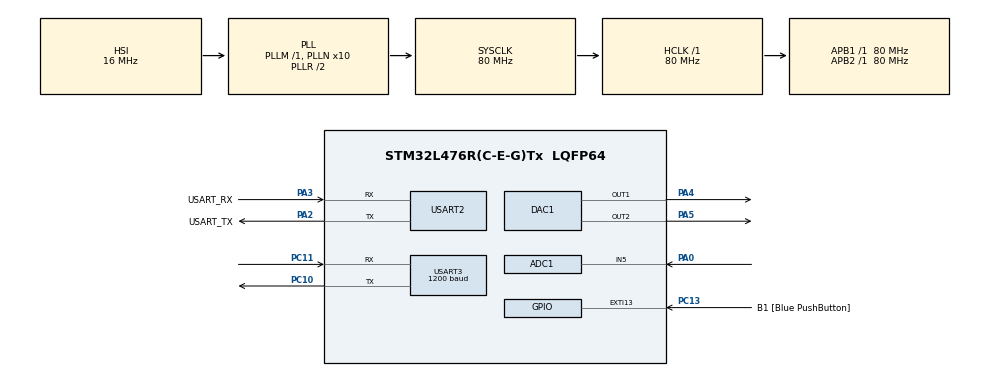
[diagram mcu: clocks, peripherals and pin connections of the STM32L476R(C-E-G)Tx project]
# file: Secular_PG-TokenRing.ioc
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ADC1.Channel-0\#ChannelRegularConversion=ADC_CHANNEL_5
ADC1.ContinuousConvMode=DISABLE
ADC1.DMAContinuousRequests=ENABLE
ADC1.ExternalTrigConv=ADC_EXTERNALTRIG_T4_TRGO
ADC1.NbrOfConversionFlag=1
ADC1.OffsetNumber-0\#ChannelRegularConversion=ADC_OFFSET_NONE
ADC1.Rank-0\#ChannelRegularConversion=1
ADC1.SamplingTime-0\#ChannelRegularConversion=ADC_SAMPLETIME_2CYCLES_5
ADC1.master=1
DAC1.DAC_Channel-DAC_OUT2=DAC_CHANNEL_2
DAC1.DAC_SampleAndHold-DAC_OUT1=DAC_SAMPLEANDHOLD_DISABLE
DAC1.DAC_Trigger-DAC_OUT1=DAC_TRIGGER_T2_TRGO
DAC1.DAC_Trigger-DAC_OUT2=DAC_TRIGGER_T5_TRGO
DAC1.WaveGeneration-DAC_OUT1=NoiseWaveGeneration
DAC1.WaveGeneration-DAC_OUT2=NoiseWaveGeneration
Dma.ADC1.2.Direction=DMA_PERIPH_TO_MEMORY
Dma.ADC1.2.Instance=DMA1_Channel1
Dma.ADC1.2.MemDataAlignment=DMA_MDATAALIGN_HALFWORD
Dma.ADC1.2.MemInc=DMA_MINC_ENABLE
Dma.ADC1.2.Mode=DMA_NORMAL
Dma.ADC1.2.PeriphDataAlignment=DMA_PDATAALIGN_HALFWORD
Dma.ADC1.2.PeriphInc=DMA_PINC_DISABLE
Dma.ADC1.2.Priority=DMA_PRIORITY_HIGH
Dma.DAC_CH1.0.Direction=DMA_MEMORY_TO_PERIPH
Dma.DAC_CH1.0.Instance=DMA1_Channel3
Dma.DAC_CH1.0.MemDataAlignment=DMA_MDATAALIGN_HALFWORD
Dma.DAC_CH1.0.MemInc=DMA_MINC_ENABLE
Dma.DAC_CH1.0.Mode=DMA_CIRCULAR
Dma.DAC_CH1.0.PeriphDataAlignment=DMA_PDATAALIGN_HALFWORD
Dma.DAC_CH1.0.PeriphInc=DMA_PINC_DISABLE
Dma.DAC_CH1.0.Priority=DMA_PRIORITY_HIGH
Dma.DAC_CH2.1.Direction=DMA_MEMORY_TO_PERIPH
Dma.DAC_CH2.1.Instance=DMA1_Channel4
Dma.DAC_CH2.1.MemDataAlignment=DMA_MDATAALIGN_HALFWORD
Dma.DAC_CH2.1.MemInc=DMA_MINC_ENABLE
Dma.DAC_CH2.1.Mode=DMA_CIRCULAR
Dma.DAC_CH2.1.PeriphDataAlignment=DMA_PDATAALIGN_HALFWORD
Dma.DAC_CH2.1.PeriphInc=DMA_PINC_DISABLE
Dma.DAC_CH2.1.Priority=DMA_PRIORITY_HIGH
Dma.Request0=DAC_CH1
Dma.Request1=DAC_CH2
Dma.Request2=ADC1
FREERTOS.Tasks01=defaultTask,0,1024,StartDefaultTask,Default,NULL,Dynamic,NULL,NULL
FREERTOS.configMINIMAL_STACK_SIZE=1024
FREERTOS.configTOTAL_HEAP_SIZE=30000
FREERTOS.configUSE_NEWLIB_REENTRANT=1
Mcu.Family=STM32L4
Mcu.Name=STM32L476R(C-E-G)Tx
Mcu.Package=LQFP64
NVIC.DMA1_Channel1_IRQn=true\:5\:0\:false\:false\:true\:true\:false\:true\:true
NVIC.DMA1_Channel3_IRQn=true\:5\:0\:false\:false\:true\:true\:false\:true\:true
NVIC.DMA1_Channel4_IRQn=true\:5\:0\:false\:false\:true\:true\:false\:true\:true
NVIC.PriorityGroup=NVIC_PRIORITYGROUP_4
NVIC.TIM3_IRQn=true\:15\:0\:false\:false\:true\:false\:false\:true\:true
NVIC.TimeBase=TIM3_IRQn
NVIC.TimeBaseIP=TIM3
NVIC.USART3_IRQn=true\:5\:0\:false\:false\:true\:true\:true\:true\:true
PA0.Signal=ADCx_IN5
PA13\ (JTMS-SWDIO).GPIO_Label=TMS
PA13\ (JTMS-SWDIO).Mode=Serial_Wire
PA13\ (JTMS-SWDIO).Signal=SYS_JTMS-SWDIO
PA14\ (JTCK-SWCLK).GPIO_Label=TCK
PA14\ (JTCK-SWCLK).Mode=Serial_Wire
PA14\ (JTCK-SWCLK).Signal=SYS_JTCK-SWCLK
PA2.GPIO_Label=USART_TX
PA2.GPIO_Mode=GPIO_MODE_AF_PP
PA2.GPIO_PuPd=GPIO_NOPULL
PA2.GPIO_Speed=GPIO_SPEED_FREQ_VERY_HIGH
PA2.Mode=Asynchronous
PA2.Signal=USART2_TX
PA3.GPIO_Label=USART_RX
PA3.GPIO_Mode=GPIO_MODE_AF_PP
PA3.GPIO_PuPd=GPIO_NOPULL
PA3.GPIO_Speed=GPIO_SPEED_FREQ_VERY_HIGH
PA3.Mode=Asynchronous
PA3.Signal=USART2_RX
PA4.Signal=COMP_DAC11_group
PA5.Signal=COMP_DAC12_group
PB3\ (JTDO-TRACESWO).GPIO_Label=SWO
PB3\ (JTDO-TRACESWO).Signal=SYS_JTDO-SWO
PC10.Mode=Asynchronous
PC10.Signal=USART3_TX
PC11.Mode=Asynchronous
PC11.Signal=USART3_RX
PC13.GPIO_Label=B1 [Blue PushButton]
PC13.GPIO_ModeDefaultEXTI=GPIO_MODE_IT_FALLING
PC13.GPIO_PuPd=GPIO_NOPULL
PC13.Signal=GPXTI13
PC14-OSC32_IN\ (PC14).Mode=LSE-External-Oscillator
PC14-OSC32_IN\ (PC14).Signal=RCC_OSC32_IN
PC15-OSC32_OUT\ (PC15).Mode=LSE-External-Oscillator
PC15-OSC32_OUT\ (PC15).Signal=RCC_OSC32_OUT
PH0-OSC_IN\ (PH0).Signal=RCC_OSC_IN
PH1-OSC_OUT\ (PH1).Signal=RCC_OSC_OUT
ProjectManager.HeapSize=0x200
ProjectManager.StackSize=0x400
ProjectManager.TargetToolchain=STM32CubeIDE
RCC.ADCFreq_Value=64000000
RCC.AHBFreq_Value=80000000
RCC.APB1Freq_Value=80000000
RCC.APB1TimFreq_Value=80000000
RCC.APB2Freq_Value=80000000
RCC.APB2TimFreq_Value=80000000
RCC.CortexFreq_Value=80000000
RCC.HCLKFreq_Value=80000000
RCC.HSE_VALUE=8000000
RCC.HSI_VALUE=16000000
RCC.MSI_VALUE=4000000
RCC.PLLN=10
RCC.PLLSAI1Q=RCC_PLLQ_DIV4
RCC.PLLSourceVirtual=RCC_PLLSOURCE_HSI
RCC.PREFETCH_ENABLE=1
RCC.SYSCLKFreq_VALUE=80000000
RCC.SYSCLKSource=RCC_SYSCLKSOURCE_PLLCLK
RCC.USART3CLockSelection=RCC_USART3CLKSOURCE_HSI
RCC.USBFreq_Value=32000000
RCC.VCOOutputFreq_Value=160000000
SH.ADCx_IN5.0=ADC1_IN5,IN5-Single-Ended
SH.COMP_DAC11_group.0=DAC1_OUT1,DAC_OUT1
SH.COMP_DAC12_group.0=DAC1_OUT2,DAC_OUT2
TIM2.AutoReloadPreload=TIM_AUTORELOAD_PRELOAD_DISABLE
TIM2.Channel-Output\ Compare1\ No\ Output=TIM_CHANNEL_1
TIM2.CounterMode=TIM_COUNTERMODE_UP
TIM2.OCMode_1=TIM_OCMODE_RETRIGERRABLE_OPM1
TIM2.Period=1000
TIM2.Prescaler=79
TIM2.TIM_MasterOutputTrigger=TIM_TRGO_UPDATE
TIM4.Period=7999
TIM4.Prescaler=0
TIM4.TIM_MasterOutputTrigger=TIM_TRGO_UPDATE
TIM5.Prescaler=79
TIM5.TIM_MasterOutputTrigger=TIM_TRGO_UPDATE
USART2.VirtualMode-Asynchronous=VM_ASYNC
USART3.BaudRate=1200
USART3.VirtualMode-Asynchronous=VM_ASYNC
VP_FREERTOS_VS_CMSIS_V1.Mode=CMSIS_V1
VP_RNG_VS_RNG.Mode=RNG_Activate
VP_SYS_VS_tim3.Mode=TIM3
VP_TIM1_VS_ClockSourceINT.Mode=Internal
VP_TIM2_VS_ClockSourceINT.Mode=Internal
VP_TIM2_VS_no_output1.Mode=Output Compare1 No Output
VP_TIM4_VS_ClockSourceINT.Mode=Internal
VP_TIM5_VS_ClockSourceINT.Mode=Internal
board=NUCLEO-L476RG

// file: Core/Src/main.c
/* USER CODE BEGIN Header */
/**
  ******************************************************************************
  * @file           : main.c
  * @brief          : Main program body
  ******************************************************************************
  * @attention
  *
  * Copyright (c) 2023 STMicroelectronics.
  * All rights reserved.
  *
  * This software is licensed under terms that can be found in the LICENSE file
  * in the root directory of this software component.
  * If no LICENSE file comes with this software, it is provided AS-IS.
  *
  ******************************************************************************
  */
/* USER CODE END Header */
#include "main.h"
#include "cmsis_os.h"

ADC_HandleTypeDef hadc1;
DMA_HandleTypeDef hdma_adc1;

DAC_HandleTypeDef hdac1;
DMA_HandleTypeDef hdma_dac_ch1;
DMA_HandleTypeDef hdma_dac_ch2;

RNG_HandleTypeDef hrng;

TIM_HandleTypeDef htim1;
TIM_HandleTypeDef htim2;
TIM_HandleTypeDef htim4;
TIM_HandleTypeDef htim5;

UART_HandleTypeDef huart2;
UART_HandleTypeDef huart3;

osThreadId defaultTaskHandle;

void SystemClock_Config(void);
void PeriphCommonClock_Config(void);
static void MX_GPIO_Init(void);
static void MX_DMA_Init(void);
static void MX_USART2_UART_Init(void);
static void MX_DAC1_Init(void);
static void MX_RNG_Init(void);
static void MX_TIM2_Init(void);
static void MX_TIM1_Init(void);
static void MX_TIM5_Init(void);
static void MX_ADC1_Init(void);
static void MX_TIM4_Init(void);
static void MX_USART3_UART_Init(void);
void StartDefaultTask(void const * argument);

int main(void)
{

  /* MCU Configuration--------------------------------------------------------*/

  /* Reset of all peripherals, Initializes the Flash interface and the Systick. */
  HAL_Init();

  /* Configure the system clock */
  SystemClock_Config();

/* Configure the peripherals common clocks */
  PeriphCommonClock_Config();

  /* Initialize all configured peripherals */
  MX_GPIO_Init();
  MX_DMA_Init();
  MX_USART2_UART_Init();
  MX_DAC1_Init();
  MX_RNG_Init();
  MX_TIM2_Init();
  MX_TIM1_Init();
  MX_TIM5_Init();
  MX_ADC1_Init();
  MX_TIM4_Init();
  MX_USART3_UART_Init();

  /* Create the thread(s) */
  /* definition and creation of defaultTask */
  osThreadDef(defaultTask, StartDefaultTask, osPriorityNormal, 0, 1024);
  defaultTaskHandle = osThreadCreate(osThread(defaultTask), NULL);

  /* USER CODE BEGIN RTOS_THREADS */
  /* add threads, ... */
  app_init();
  /* USER CODE END RTOS_THREADS */

  /* Start scheduler */
  osKernelStart();
  /* We should never get here as control is now taken by the scheduler */
  /* Infinite loop */
  while (1)
  {

  }
}

void SystemClock_Config(void)
{
  RCC_OscInitTypeDef RCC_OscInitStruct = {0};
  RCC_ClkInitTypeDef RCC_ClkInitStruct = {0};

  /** Configure the main internal regulator output voltage
  */
  if (HAL_PWREx_ControlVoltageScaling(PWR_REGULATOR_VOLTAGE_SCALE1) != HAL_OK)
  {
    Error_Handler();
  }

  /** Initializes the RCC Oscillators according to the specified parameters
  * in the RCC_OscInitTypeDef structure.
  */
  RCC_OscInitStruct.OscillatorType = RCC_OSCILLATORTYPE_HSI;
  RCC_OscInitStruct.HSIState = RCC_HSI_ON;
  RCC_OscInitStruct.HSICalibrationValue = RCC_HSICALIBRATION_DEFAULT;
  RCC_OscInitStruct.PLL.PLLState = RCC_PLL_ON;
  RCC_OscInitStruct.PLL.PLLSource = RCC_PLLSOURCE_HSI;
  RCC_OscInitStruct.PLL.PLLM = 1;
  RCC_OscInitStruct.PLL.PLLN = 10;
  RCC_OscInitStruct.PLL.PLLP = RCC_PLLP_DIV7;
  RCC_OscInitStruct.PLL.PLLQ = RCC_PLLQ_DIV2;
  RCC_OscInitStruct.PLL.PLLR = RCC_PLLR_DIV2;
  if (HAL_RCC_OscConfig(&RCC_OscInitStruct) != HAL_OK)
  {
    Error_Handler();
  }

  /** Initializes the CPU, AHB and APB buses clocks
  */
  RCC_ClkInitStruct.ClockType = RCC_CLOCKTYPE_HCLK|RCC_CLOCKTYPE_SYSCLK
                              |RCC_CLOCKTYPE_PCLK1|RCC_CLOCKTYPE_PCLK2;
  RCC_ClkInitStruct.SYSCLKSource = RCC_SYSCLKSOURCE_PLLCLK;
  RCC_ClkInitStruct.AHBCLKDivider = RCC_SYSCLK_DIV1;
  RCC_ClkInitStruct.APB1CLKDivider = RCC_HCLK_DIV1;
  RCC_ClkInitStruct.APB2CLKDivider = RCC_HCLK_DIV1;

  if (HAL_RCC_ClockConfig(&RCC_ClkInitStruct, FLASH_LATENCY_4) != HAL_OK)
  {
    Error_Handler();
  }
}

void PeriphCommonClock_Config(void)
{
  RCC_PeriphCLKInitTypeDef PeriphClkInit = {0};

  /** Initializes the peripherals clock
  */
  PeriphClkInit.PeriphClockSelection = RCC_PERIPHCLK_RNG|RCC_PERIPHCLK_ADC;
  PeriphClkInit.AdcClockSelection = RCC_ADCCLKSOURCE_PLLSAI1;
  PeriphClkInit.RngClockSelection = RCC_RNGCLKSOURCE_PLLSAI1;
  PeriphClkInit.PLLSAI1.PLLSAI1Source = RCC_PLLSOURCE_HSI;
  PeriphClkInit.PLLSAI1.PLLSAI1M = 1;
  PeriphClkInit.PLLSAI1.PLLSAI1N = 8;
  PeriphClkInit.PLLSAI1.PLLSAI1P = RCC_PLLP_DIV7;
  PeriphClkInit.PLLSAI1.PLLSAI1Q = RCC_PLLQ_DIV4;
  PeriphClkInit.PLLSAI1.PLLSAI1R = RCC_PLLR_DIV2;
  PeriphClkInit.PLLSAI1.PLLSAI1ClockOut = RCC_PLLSAI1_48M2CLK|RCC_PLLSAI1_ADC1CLK;
  if (HAL_RCCEx_PeriphCLKConfig(&PeriphClkInit) != HAL_OK)
  {
    Error_Handler();
  }
}

static void MX_ADC1_Init(void)
{

  ADC_MultiModeTypeDef multimode = {0};
  ADC_ChannelConfTypeDef sConfig = {0};

  /** Common config
  */
  hadc1.Instance = ADC1;
  hadc1.Init.ClockPrescaler = ADC_CLOCK_ASYNC_DIV1;
  hadc1.Init.Resolution = ADC_RESOLUTION_12B;
  hadc1.Init.DataAlign = ADC_DATAALIGN_RIGHT;
  hadc1.Init.ScanConvMode = ADC_SCAN_DISABLE;
  hadc1.Init.EOCSelection = ADC_EOC_SINGLE_CONV;
  hadc1.Init.LowPowerAutoWait = DISABLE;
  hadc1.Init.ContinuousConvMode = DISABLE;
  hadc1.Init.NbrOfConversion = 1;
  hadc1.Init.DiscontinuousConvMode = DISABLE;
  hadc1.Init.ExternalTrigConv = ADC_EXTERNALTRIG_T4_TRGO;
  hadc1.Init.ExternalTrigConvEdge = ADC_EXTERNALTRIGCONVEDGE_RISING;
  hadc1.Init.DMAContinuousRequests = ENABLE;
  hadc1.Init.Overrun = ADC_OVR_DATA_PRESERVED;
  hadc1.Init.OversamplingMode = DISABLE;
  if (HAL_ADC_Init(&hadc1) != HAL_OK)
  {
    Error_Handler();
  }

  /** Configure the ADC multi-mode
  */
  multimode.Mode = ADC_MODE_INDEPENDENT;
  if (HAL_ADCEx_MultiModeConfigChannel(&hadc1, &multimode) != HAL_OK)
  {
    Error_Handler();
  }

  /** Configure Regular Channel
  */
  sConfig.Channel = ADC_CHANNEL_5;
  sConfig.Rank = ADC_REGULAR_RANK_1;
  sConfig.SamplingTime = ADC_SAMPLETIME_2CYCLES_5;
  sConfig.SingleDiff = ADC_SINGLE_ENDED;
  sConfig.OffsetNumber = ADC_OFFSET_NONE;
  sConfig.Offset = 0;
  if (HAL_ADC_ConfigChannel(&hadc1, &sConfig) != HAL_OK)
  {
    Error_Handler();
  }

}

static void MX_DAC1_Init(void)
{

  DAC_ChannelConfTypeDef sConfig = {0};

  /** DAC Initialization
  */
  hdac1.Instance = DAC1;
  if (HAL_DAC_Init(&hdac1) != HAL_OK)
  {
    Error_Handler();
  }

  /** DAC channel OUT1 config
  */
  sConfig.DAC_SampleAndHold = DAC_SAMPLEANDHOLD_DISABLE;
  sConfig.DAC_Trigger = DAC_TRIGGER_T2_TRGO;
  sConfig.DAC_OutputBuffer = DAC_OUTPUTBUFFER_ENABLE;
  sConfig.DAC_ConnectOnChipPeripheral = DAC_CHIPCONNECT_DISABLE;
  sConfig.DAC_UserTrimming = DAC_TRIMMING_FACTORY;
  if (HAL_DAC_ConfigChannel(&hdac1, &sConfig, DAC_CHANNEL_1) != HAL_OK)
  {
    Error_Handler();
  }

  /** Configure Noise wave generation on DAC OUT1
  */
  if (HAL_DACEx_NoiseWaveGenerate(&hdac1, DAC_CHANNEL_1, DAC_LFSRUNMASK_BIT0) != HAL_OK)
  {
    Error_Handler();
  }

  /** DAC channel OUT2 config
  */
  sConfig.DAC_Trigger = DAC_TRIGGER_T5_TRGO;
  if (HAL_DAC_ConfigChannel(&hdac1, &sConfig, DAC_CHANNEL_2) != HAL_OK)
  {
    Error_Handler();
  }

  /** Configure Noise wave generation on DAC OUT2
  */
  if (HAL_DACEx_NoiseWaveGenerate(&hdac1, DAC_CHANNEL_2, DAC_LFSRUNMASK_BIT0) != HAL_OK)
  {
    Error_Handler();
  }

}

static void MX_RNG_Init(void)
{

  hrng.Instance = RNG;
  if (HAL_RNG_Init(&hrng) != HAL_OK)
  {
    Error_Handler();
  }

}

static void MX_TIM1_Init(void)
{

  TIM_ClockConfigTypeDef sClockSourceConfig = {0};
  TIM_MasterConfigTypeDef sMasterConfig = {0};

  htim1.Instance = TIM1;
  htim1.Init.Prescaler = 0;
  htim1.Init.CounterMode = TIM_COUNTERMODE_UP;
  htim1.Init.Period = 65535;
  htim1.Init.ClockDivision = TIM_CLOCKDIVISION_DIV1;
  htim1.Init.RepetitionCounter = 0;
  htim1.Init.AutoReloadPreload = TIM_AUTORELOAD_PRELOAD_DISABLE;
  if (HAL_TIM_Base_Init(&htim1) != HAL_OK)
  {
    Error_Handler();
  }
  sClockSourceConfig.ClockSource = TIM_CLOCKSOURCE_INTERNAL;
  if (HAL_TIM_ConfigClockSource(&htim1, &sClockSourceConfig) != HAL_OK)
  {
    Error_Handler();
  }
  sMasterConfig.MasterOutputTrigger = TIM_TRGO_RESET;
  sMasterConfig.MasterOutputTrigger2 = TIM_TRGO2_RESET;
  sMasterConfig.MasterSlaveMode = TIM_MASTERSLAVEMODE_DISABLE;
  if (HAL_TIMEx_MasterConfigSynchronization(&htim1, &sMasterConfig) != HAL_OK)
  {
    Error_Handler();
  }

}

static void MX_TIM2_Init(void)
{

  TIM_ClockConfigTypeDef sClockSourceConfig = {0};
  TIM_MasterConfigTypeDef sMasterConfig = {0};
  TIM_OC_InitTypeDef sConfigOC = {0};

  htim2.Instance = TIM2;
  htim2.Init.Prescaler = 79;
  htim2.Init.CounterMode = TIM_COUNTERMODE_UP;
  htim2.Init.Period = 1000;
  htim2.Init.ClockDivision = TIM_CLOCKDIVISION_DIV1;
  htim2.Init.AutoReloadPreload = TIM_AUTORELOAD_PRELOAD_DISABLE;
  if (HAL_TIM_Base_Init(&htim2) != HAL_OK)
  {
    Error_Handler();
  }
  sClockSourceConfig.ClockSource = TIM_CLOCKSOURCE_INTERNAL;
  if (HAL_TIM_ConfigClockSource(&htim2, &sClockSourceConfig) != HAL_OK)
  {
    Error_Handler();
  }
  if (HAL_TIM_OC_Init(&htim2) != HAL_OK)
  {
    Error_Handler();
  }
  sMasterConfig.MasterOutputTrigger = TIM_TRGO_UPDATE;
  sMasterConfig.MasterSlaveMode = TIM_MASTERSLAVEMODE_DISABLE;
  if (HAL_TIMEx_MasterConfigSynchronization(&htim2, &sMasterConfig) != HAL_OK)
  {
    Error_Handler();
  }
  sConfigOC.OCMode = TIM_OCMODE_RETRIGERRABLE_OPM1;
  sConfigOC.Pulse = 0;
  sConfigOC.OCPolarity = TIM_OCPOLARITY_HIGH;
  sConfigOC.OCFastMode = TIM_OCFAST_DISABLE;
  if (HAL_TIM_OC_ConfigChannel(&htim2, &sConfigOC, TIM_CHANNEL_1) != HAL_OK)
  {
    Error_Handler();
  }

}

static void MX_TIM4_Init(void)
{

  TIM_ClockConfigTypeDef sClockSourceConfig = {0};
  TIM_MasterConfigTypeDef sMasterConfig = {0};

  htim4.Instance = TIM4;
  htim4.Init.Prescaler = 0;
  htim4.Init.CounterMode = TIM_COUNTERMODE_UP;
  htim4.Init.Period = 7999;
  htim4.Init.ClockDivision = TIM_CLOCKDIVISION_DIV1;
  htim4.Init.AutoReloadPreload = TIM_AUTORELOAD_PRELOAD_DISABLE;
  if (HAL_TIM_Base_Init(&htim4) != HAL_OK)
  {
    Error_Handler();
  }
  sClockSourceConfig.ClockSource = TIM_CLOCKSOURCE_INTERNAL;
  if (HAL_TIM_ConfigClockSource(&htim4, &sClockSourceConfig) != HAL_OK)
  {
    Error_Handler();
  }
  sMasterConfig.MasterOutputTrigger = TIM_TRGO_UPDATE;
  sMasterConfig.MasterSlaveMode = TIM_MASTERSLAVEMODE_DISABLE;
  if (HAL_TIMEx_MasterConfigSynchronization(&htim4, &sMasterConfig) != HAL_OK)
  {
    Error_Handler();
  }

}

static void MX_TIM5_Init(void)
{

  TIM_ClockConfigTypeDef sClockSourceConfig = {0};
  TIM_MasterConfigTypeDef sMasterConfig = {0};

  htim5.Instance = TIM5;
  htim5.Init.Prescaler = 79;
  htim5.Init.CounterMode = TIM_COUNTERMODE_UP;
  htim5.Init.Period = 4294967295;
  htim5.Init.ClockDivision = TIM_CLOCKDIVISION_DIV1;
  htim5.Init.AutoReloadPreload = TIM_AUTORELOAD_PRELOAD_DISABLE;
  if (HAL_TIM_Base_Init(&htim5) != HAL_OK)
  {
    Error_Handler();
  }
  sClockSourceConfig.ClockSource = TIM_CLOCKSOURCE_INTERNAL;
  if (HAL_TIM_ConfigClockSource(&htim5, &sClockSourceConfig) != HAL_OK)
  {
    Error_Handler();
  }
  sMasterConfig.MasterOutputTrigger = TIM_TRGO_UPDATE;
  sMasterConfig.MasterSlaveMode = TIM_MASTERSLAVEMODE_DISABLE;
  if (HAL_TIMEx_MasterConfigSynchronization(&htim5, &sMasterConfig) != HAL_OK)
  {
    Error_Handler();
  }

}

static void MX_USART2_UART_Init(void)
{

  huart2.Instance = USART2;
  huart2.Init.BaudRate = 115200;
  huart2.Init.WordLength = UART_WORDLENGTH_8B;
  huart2.Init.StopBits = UART_STOPBITS_1;
  huart2.Init.Parity = UART_PARITY_NONE;
  huart2.Init.Mode = UART_MODE_TX_RX;
  huart2.Init.HwFlowCtl = UART_HWCONTROL_NONE;
  huart2.Init.OverSampling = UART_OVERSAMPLING_16;
  huart2.Init.OneBitSampling = UART_ONE_BIT_SAMPLE_DISABLE;
  huart2.AdvancedInit.AdvFeatureInit = UART_ADVFEATURE_NO_INIT;
  if (HAL_UART_Init(&huart2) != HAL_OK)
  {
    Error_Handler();
  }

}

static void MX_USART3_UART_Init(void)
{

  huart3.Instance = USART3;
  huart3.Init.BaudRate = 1200;
  huart3.Init.WordLength = UART_WORDLENGTH_8B;
  huart3.Init.StopBits = UART_STOPBITS_1;
  huart3.Init.Parity = UART_PARITY_NONE;
  huart3.Init.Mode = UART_MODE_TX_RX;
  huart3.Init.HwFlowCtl = UART_HWCONTROL_NONE;
  huart3.Init.OverSampling = UART_OVERSAMPLING_16;
  huart3.Init.OneBitSampling = UART_ONE_BIT_SAMPLE_DISABLE;
  huart3.AdvancedInit.AdvFeatureInit = UART_ADVFEATURE_NO_INIT;
  if (HAL_UART_Init(&huart3) != HAL_OK)
  {
    Error_Handler();
  }

}

static void MX_DMA_Init(void)
{

  /* DMA controller clock enable */
  __HAL_RCC_DMA1_CLK_ENABLE();

  /* DMA interrupt init */
  /* DMA1_Channel1_IRQn interrupt configuration */
  HAL_NVIC_SetPriority(DMA1_Channel1_IRQn, 5, 0);
  HAL_NVIC_EnableIRQ(DMA1_Channel1_IRQn);
  /* DMA1_Channel3_IRQn interrupt configuration */
  HAL_NVIC_SetPriority(DMA1_Channel3_IRQn, 5, 0);
  HAL_NVIC_EnableIRQ(DMA1_Channel3_IRQn);
  /* DMA1_Channel4_IRQn interrupt configuration */
  HAL_NVIC_SetPriority(DMA1_Channel4_IRQn, 5, 0);
  HAL_NVIC_EnableIRQ(DMA1_Channel4_IRQn);

}

static void MX_GPIO_Init(void)
{
  GPIO_InitTypeDef GPIO_InitStruct = {0};

  /* GPIO Ports Clock Enable */
  __HAL_RCC_GPIOC_CLK_ENABLE();
  __HAL_RCC_GPIOH_CLK_ENABLE();
  __HAL_RCC_GPIOA_CLK_ENABLE();
  __HAL_RCC_GPIOB_CLK_ENABLE();

  /*Configure GPIO pin : B1_Pin */
  GPIO_InitStruct.Pin = B1_Pin;
  GPIO_InitStruct.Mode = GPIO_MODE_IT_FALLING;
  GPIO_InitStruct.Pull = GPIO_NOPULL;
  HAL_GPIO_Init(B1_GPIO_Port, &GPIO_InitStruct);

}

void StartDefaultTask(void const * argument)
{
  for(;;)
  {
    osDelay(1);
  }
}

void HAL_TIM_PeriodElapsedCallback(TIM_HandleTypeDef *htim)
{
  if (htim->Instance == TIM3) {
    HAL_IncTick();
  }
}

void Error_Handler(void)
{
  __disable_irq();
  while (1)
  {
  }
}
